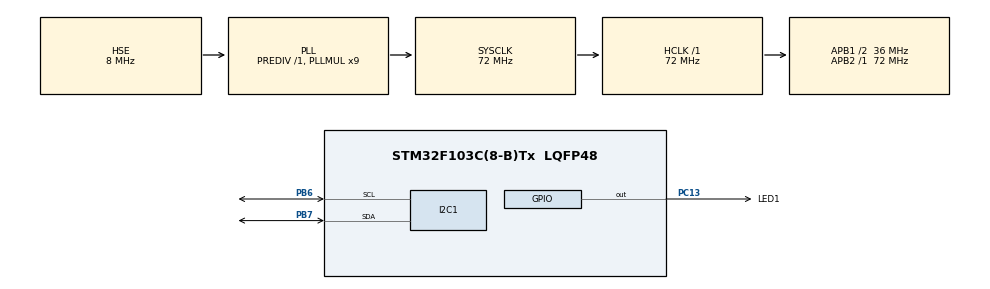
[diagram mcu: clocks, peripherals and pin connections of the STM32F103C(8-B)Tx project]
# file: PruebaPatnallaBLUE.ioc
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Dma.I2C1_RX.0.Direction=DMA_PERIPH_TO_MEMORY
Dma.I2C1_RX.0.Instance=DMA1_Channel7
Dma.I2C1_RX.0.MemDataAlignment=DMA_MDATAALIGN_BYTE
Dma.I2C1_RX.0.MemInc=DMA_MINC_ENABLE
Dma.I2C1_RX.0.Mode=DMA_NORMAL
Dma.I2C1_RX.0.PeriphDataAlignment=DMA_PDATAALIGN_BYTE
Dma.I2C1_RX.0.PeriphInc=DMA_PINC_DISABLE
Dma.I2C1_RX.0.Priority=DMA_PRIORITY_LOW
Dma.I2C1_TX.1.Direction=DMA_MEMORY_TO_PERIPH
Dma.I2C1_TX.1.Instance=DMA1_Channel6
Dma.I2C1_TX.1.MemDataAlignment=DMA_MDATAALIGN_BYTE
Dma.I2C1_TX.1.MemInc=DMA_MINC_ENABLE
Dma.I2C1_TX.1.Mode=DMA_NORMAL
Dma.I2C1_TX.1.PeriphDataAlignment=DMA_PDATAALIGN_BYTE
Dma.I2C1_TX.1.PeriphInc=DMA_PINC_DISABLE
Dma.I2C1_TX.1.Priority=DMA_PRIORITY_LOW
Dma.Request0=I2C1_RX
Dma.Request1=I2C1_TX
I2C1.I2C_Mode=I2C_Fast
Mcu.Family=STM32F1
Mcu.Name=STM32F103C(8-B)Tx
Mcu.Package=LQFP48
NVIC.DMA1_Channel6_IRQn=true\:0\:0\:false\:false\:true\:false\:true\:true
NVIC.DMA1_Channel7_IRQn=true\:0\:0\:false\:false\:true\:false\:true\:true
NVIC.I2C1_ER_IRQn=true\:0\:0\:false\:false\:true\:true\:true\:true
NVIC.I2C1_EV_IRQn=true\:0\:0\:false\:false\:true\:true\:true\:true
NVIC.PriorityGroup=NVIC_PRIORITYGROUP_4
NVIC.TIM4_IRQn=true\:0\:0\:false\:false\:true\:true\:true\:true
PA13.Mode=Serial_Wire
PA13.Signal=SYS_JTMS-SWDIO
PA14.Mode=Serial_Wire
PA14.Signal=SYS_JTCK-SWCLK
PB6.Mode=I2C
PB6.Signal=I2C1_SCL
PB7.Mode=I2C
PB7.Signal=I2C1_SDA
PC13-TAMPER-RTC.GPIO_Label=LED1
PC13-TAMPER-RTC.Signal=GPIO_Output
PC14-OSC32_IN.Mode=LSE-External-Oscillator
PC14-OSC32_IN.Signal=RCC_OSC32_IN
PC15-OSC32_OUT.Mode=LSE-External-Oscillator
PC15-OSC32_OUT.Signal=RCC_OSC32_OUT
PD0-OSC_IN.Mode=HSE-External-Oscillator
PD0-OSC_IN.Signal=RCC_OSC_IN
PD1-OSC_OUT.Mode=HSE-External-Oscillator
PD1-OSC_OUT.Signal=RCC_OSC_OUT
ProjectManager.HeapSize=0x200
ProjectManager.StackSize=0x400
ProjectManager.TargetToolchain=STM32CubeIDE
RCC.AHBFreq_Value=72000000
RCC.APB1CLKDivider=RCC_HCLK_DIV2
RCC.APB1Freq_Value=36000000
RCC.APB1TimFreq_Value=72000000
RCC.APB2Freq_Value=72000000
RCC.APB2TimFreq_Value=72000000
RCC.HCLKFreq_Value=72000000
RCC.PLLMUL=RCC_PLL_MUL9
RCC.PLLSourceVirtual=RCC_PLLSOURCE_HSE
RCC.SYSCLKFreq_VALUE=72000000
RCC.SYSCLKSource=RCC_SYSCLKSOURCE_PLLCLK
RCC.USBFreq_Value=72000000
TIM4.Period=7200
TIM4.Prescaler=1000
VP_TIM4_VS_ClockSourceINT.Mode=Internal
board=custom

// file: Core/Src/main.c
/* USER CODE BEGIN Header */
/**
  ******************************************************************************
  * @file           : main.c
  * @brief          : Main program body
  ******************************************************************************
  * @attention
  *
  * Copyright (c) 2025 STMicroelectronics.
  * All rights reserved.
  *
  * This software is licensed under terms that can be found in the LICENSE file
  * in the root directory of this software component.
  * If no LICENSE file comes with this software, it is provided AS-IS.
  *
  ******************************************************************************
  */
/* USER CODE END Header */
#include "main.h"

/* USER CODE BEGIN Includes */
#include "utilities.h"
#include "display.h"

/* USER CODE END Includes */

/* USER CODE BEGIN PD */
#define IS10MS					generalFlags.bit.b0
#define REFRESH_OLED			generalFlags.bit.b1
/* USER CODE END PD */

I2C_HandleTypeDef hi2c1;
DMA_HandleTypeDef hdma_i2c1_rx;
DMA_HandleTypeDef hdma_i2c1_tx;

TIM_HandleTypeDef htim4;

/* USER CODE BEGIN PV */
const unsigned char uner_logo[] = {
		0xff, 0xff, 0xff, 0xff, 0xff, 0xff, 0xff, 0xff, 0xff, 0xff, 0xff, 0xff, 0xff, 0xff, 0xff, 0xff,
		0xff, 0xff, 0xff, 0xff, 0xff, 0xff, 0xff, 0xff, 0xff, 0xff, 0xff, 0xff, 0xff, 0xff, 0xff, 0xff,
		0xff, 0xff, 0xff, 0xff, 0xff, 0xff, 0xff, 0xff, 0xff, 0xff, 0xff, 0xff, 0xff, 0xff, 0xff, 0xff,
		0xff, 0xff, 0xff, 0xff, 0xff, 0xff, 0xff, 0xff, 0xff, 0xff, 0xff, 0xff, 0xff, 0xff, 0xff, 0xff,
		0xff, 0xff, 0xff, 0xff, 0xff, 0xff, 0xff, 0xff, 0xff, 0xff, 0xff, 0xff, 0xff, 0xff, 0xff, 0xff,
		0xff, 0xff, 0xff, 0xff, 0xff, 0xff, 0xff, 0xff, 0xff, 0xff, 0xff, 0xff, 0xff, 0xff, 0xff, 0xff,
		0xff, 0xff, 0xff, 0xff, 0xff, 0xff, 0xff, 0xff, 0xff, 0xff, 0xff, 0xff, 0xff, 0xff, 0xff, 0xff,
		0xff, 0xff, 0xff, 0xff, 0xff, 0xff, 0xff, 0xff, 0xff, 0xff, 0xff, 0xff, 0xff, 0xff, 0xff, 0xff,
		0xff, 0xff, 0xff, 0xff, 0xff, 0xff, 0xff, 0xff, 0xff, 0xff, 0xff, 0xff, 0xff, 0xff, 0xff, 0xff,
		0xff, 0xff, 0xff, 0xff, 0xff, 0xff, 0xff, 0xff, 0xff, 0xff, 0xff, 0xff, 0xff, 0xff, 0xff, 0xff,
		0xff, 0xff, 0xff, 0xff, 0xff, 0xff, 0xff, 0xff, 0xff, 0xff, 0xff, 0xff, 0xff, 0xff, 0xff, 0xff,
		0xff, 0xff, 0xff, 0xff, 0xff, 0xff, 0xff, 0xff, 0xff, 0xff, 0xff, 0xff, 0xff, 0xff, 0xff, 0xff,
		0xff, 0xff, 0xff, 0xff, 0xff, 0xff, 0xff, 0x07, 0xff, 0xf8, 0x3f, 0xff, 0xff, 0xff, 0xff, 0xff,
		0xff, 0xff, 0xff, 0xff, 0xff, 0xff, 0xfc, 0x01, 0xff, 0xe0, 0x0f, 0xff, 0xff, 0xff, 0xff, 0xff,
		0xff, 0xff, 0xff, 0xff, 0xff, 0xff, 0xf8, 0x00, 0xff, 0x80, 0x0f, 0xff, 0xff, 0xff, 0xff, 0xff,
		0xff, 0xff, 0xff, 0xff, 0xff, 0xe7, 0xc0, 0x00, 0x3e, 0x00, 0x0f, 0xff, 0xff, 0xff, 0xff, 0xff,
		0xff, 0xff, 0xff, 0xff, 0xff, 0xe0, 0x00, 0x00, 0x00, 0x00, 0x0f, 0xff, 0xff, 0xff, 0xff, 0xff,
		0xff, 0xff, 0xff, 0xff, 0xff, 0xe0, 0x01, 0xfc, 0x00, 0x0f, 0xef, 0xff, 0xff, 0xff, 0xff, 0xff,
		0xff, 0xff, 0xff, 0xff, 0xff, 0xe0, 0x03, 0xfe, 0x00, 0x3f, 0xff, 0xff, 0xff, 0xff, 0xff, 0xff,
		0xff, 0xff, 0xff, 0xff, 0xff, 0xf0, 0x0f, 0xff, 0x80, 0x7f, 0xff, 0xff, 0xff, 0xff, 0xff, 0xff,
		0xff, 0xff, 0xff, 0xff, 0xff, 0xfc, 0x3f, 0xff, 0xe3, 0xff, 0xff, 0xff, 0xff, 0xff, 0xff, 0xff,
		0xff, 0xff, 0xff, 0xff, 0xff, 0xff, 0xff, 0xff, 0xff, 0xff, 0xff, 0xff, 0xff, 0xff, 0xff, 0xff,
		0xff, 0xff, 0xff, 0xff, 0xff, 0xff, 0xff, 0x07, 0xff, 0xf8, 0x3f, 0xff, 0xff, 0xff, 0xff, 0xff,
		0xff, 0xff, 0xff, 0xff, 0xff, 0xff, 0xfc, 0x01, 0xff, 0xe0, 0x0f, 0xff, 0xff, 0xff, 0xff, 0xff,
		0xff, 0xff, 0xff, 0xff, 0xff, 0xff, 0xf8, 0xf8, 0xff, 0xc7, 0xcf, 0xff, 0xff, 0xff, 0xff, 0xff,
		0xff, 0xff, 0xff, 0xff, 0xff, 0xe7, 0xe3, 0xfe, 0x3f, 0x1f, 0xff, 0xff, 0xff, 0xff, 0xff, 0xff,
		0xff, 0xff, 0xff, 0xff, 0xff, 0xe0, 0x07, 0xff, 0x00, 0x7f, 0xff, 0xff, 0xff, 0xff, 0xff, 0xff,
		0xff, 0xff, 0xff, 0xff, 0xff, 0xf8, 0x1f, 0xff, 0xc1, 0xff, 0xff, 0xff, 0xff, 0xff, 0xff, 0xff,
		0xff, 0xff, 0xff, 0xff, 0xff, 0xff, 0xff, 0xff, 0xff, 0xff, 0xff, 0xff, 0xff, 0xff, 0xff, 0xff,
		0xff, 0xff, 0xff, 0xff, 0xff, 0xff, 0xff, 0xff, 0xff, 0xff, 0xff, 0xff, 0xff, 0xff, 0xff, 0xff,
		0xff, 0xff, 0xff, 0xff, 0xff, 0xff, 0xff, 0xff, 0xff, 0xff, 0xff, 0xff, 0xff, 0xff, 0xff, 0xff,
		0xff, 0xff, 0xff, 0xff, 0xff, 0xff, 0xff, 0xff, 0xff, 0xff, 0xff, 0xff, 0xff, 0xff, 0xff, 0xff,
		0xff, 0xff, 0xff, 0xff, 0xff, 0xff, 0xff, 0xff, 0xff, 0xff, 0xff, 0xff, 0xff, 0xff, 0xff, 0xff,
		0xff, 0xff, 0xff, 0xff, 0xff, 0xff, 0xff, 0xff, 0xff, 0xff, 0xff, 0xff, 0xff, 0xff, 0xff, 0xff,
		0xff, 0xff, 0xff, 0xff, 0xff, 0xff, 0xff, 0xff, 0xff, 0xff, 0xff, 0xff, 0xff, 0xff, 0xff, 0xff,
		0xff, 0xff, 0xff, 0xff, 0xff, 0xe7, 0xdc, 0x79, 0xc0, 0x30, 0x3f, 0xff, 0xff, 0xff, 0xff, 0xff,
		0xff, 0xff, 0xff, 0xff, 0xff, 0xe7, 0xdc, 0x79, 0xc0, 0x30, 0x1f, 0xff, 0xff, 0xff, 0xff, 0xff,
		0xff, 0xff, 0xff, 0xff, 0xff, 0xe7, 0xdc, 0x79, 0xc7, 0xf3, 0x8f, 0xff, 0xff, 0xff, 0xff, 0xff,
		0xff, 0xff, 0xff, 0xff, 0xff, 0xe7, 0xdc, 0x39, 0xc7, 0xf3, 0x8f, 0xff, 0xff, 0xff, 0xff, 0xff,
		0xff, 0xff, 0xff, 0xff, 0xff, 0xe7, 0xdc, 0x39, 0xc7, 0xf3, 0x8f, 0xff, 0xff, 0xff, 0xff, 0xff,
		0xff, 0xff, 0xff, 0xff, 0xff, 0xe7, 0xdc, 0x99, 0xc7, 0xf3, 0x8f, 0xff, 0xff, 0xff, 0xff, 0xff,
		0xff, 0xff, 0xff, 0xff, 0xff, 0xe7, 0xdc, 0x99, 0xc0, 0x73, 0x8f, 0xff, 0xff, 0xff, 0xff, 0xff,
		0xff, 0xff, 0xff, 0xff, 0xff, 0xe7, 0xdc, 0xc9, 0xc0, 0x70, 0x1f, 0xff, 0xff, 0xff, 0xff, 0xff,
		0xff, 0xff, 0xff, 0xff, 0xff, 0xe7, 0xdc, 0xc9, 0xc0, 0x70, 0x3f, 0xff, 0xff, 0xff, 0xff, 0xff,
		0xff, 0xff, 0xff, 0xff, 0xff, 0xe7, 0xdc, 0xe1, 0xc7, 0xf3, 0x1f, 0xff, 0xff, 0xff, 0xff, 0xff,
		0xff, 0xff, 0xff, 0xff, 0xff, 0xe7, 0xdc, 0xe1, 0xc7, 0xf3, 0x1f, 0xff, 0xff, 0xff, 0xff, 0xff,
		0xff, 0xff, 0xff, 0xff, 0xff, 0xe7, 0xdc, 0xf1, 0xc7, 0xf3, 0x1f, 0xff, 0xff, 0xff, 0xff, 0xff,
		0xff, 0xff, 0xff, 0xff, 0xff, 0xe7, 0xdc, 0xf1, 0xc7, 0xf3, 0x9f, 0xff, 0xff, 0xff, 0xff, 0xff,
		0xff, 0xff, 0xff, 0xff, 0xff, 0xf3, 0x9c, 0xf9, 0xc0, 0x33, 0x8f, 0xff, 0xff, 0xff, 0xff, 0xff,
		0xff, 0xff, 0xff, 0xff, 0xff, 0xf0, 0x1c, 0xf9, 0xc0, 0x33, 0x8f, 0xff, 0xff, 0xff, 0xff, 0xff,
		0xff, 0xff, 0xff, 0xff, 0xff, 0xf8, 0x3e, 0xf9, 0xc0, 0x33, 0xcf, 0xff, 0xff, 0xff, 0xff, 0xff,
		0xff, 0xff, 0xff, 0xff, 0xff, 0xff, 0xff, 0xff, 0xff, 0xff, 0xff, 0xff, 0xff, 0xff, 0xff, 0xff,
		0xff, 0xff, 0xff, 0xff, 0xff, 0xff, 0xff, 0xff, 0xff, 0xff, 0xff, 0xff, 0xff, 0xff, 0xff, 0xff,
		0xff, 0xff, 0xff, 0xff, 0xff, 0xff, 0xff, 0xff, 0xff, 0xff, 0xff, 0xff, 0xff, 0xff, 0xff, 0xff,
		0xff, 0xff, 0xff, 0xff, 0xff, 0xff, 0xff, 0xff, 0xff, 0xff, 0xff, 0xff, 0xff, 0xff, 0xff, 0xff,
		0xff, 0xff, 0xff, 0xff, 0xff, 0xff, 0xff, 0xff, 0xff, 0xff, 0xff, 0xff, 0xff, 0xff, 0xff, 0xff,
		0xff, 0xff, 0xff, 0xff, 0xff, 0xff, 0xff, 0xff, 0xff, 0xff, 0xff, 0xff, 0xff, 0xff, 0xff, 0xff,
		0xff, 0xff, 0xff, 0xff, 0xff, 0xff, 0xff, 0xff, 0xff, 0xff, 0xff, 0xff, 0xff, 0xff, 0xff, 0xff,
		0xff, 0xff, 0xff, 0xff, 0xff, 0xff, 0xff, 0xff, 0xff, 0xff, 0xff, 0xff, 0xff, 0xff, 0xff, 0xff,
		0xff, 0xff, 0xff, 0xff, 0xff, 0xff, 0xff, 0xff, 0xff, 0xff, 0xff, 0xff, 0xff, 0xff, 0xff, 0xff,
		0xff, 0xff, 0xff, 0xff, 0xff, 0xff, 0xff, 0xff, 0xff, 0xff, 0xff, 0xff, 0xff, 0xff, 0xff, 0xff,
		0xff, 0xff, 0xff, 0xff, 0xff, 0xff, 0xff, 0xff, 0xff, 0xff, 0xff, 0xff, 0xff, 0xff, 0xff, 0xff,
		0xff, 0xff, 0xff, 0xff, 0xff, 0xff, 0xff, 0xff, 0xff, 0xff, 0xff, 0xff, 0xff, 0xff, 0xff, 0xff,
		0xff, 0xff, 0xff, 0xff, 0xff, 0xff, 0xff, 0xff, 0xff, 0xff, 0xff, 0xff, 0xff, 0xff, 0xff, 0xff
};

struct{
	uint8_t buffer[SSD1306_WIDTH * SSD1306_HEIGHT / 8];
}Display;

uint8_t is100ms = 10, is1s = 10;

u_flag generalFlags;
/* USER CODE END PV */

void SystemClock_Config(void);
static void MX_GPIO_Init(void);
static void MX_DMA_Init(void);
static void MX_I2C1_Init(void);
static void MX_TIM4_Init(void);
/* USER CODE BEGIN PFP */
void TASK_10ms();

e_system I2C_1_Abstract_Master_Transmit(uint16_t Dev_Address, uint8_t *p_Data, uint16_t _Size);

e_system I2C_1_Abstract_Master_Transmit_Blocking(uint16_t Dev_Address, uint8_t *p_Data, uint16_t _Size, uint32_t _Timeout);

e_system I2C_1_Abstract_Mem_Read_Blocking(uint16_t Dev_Address, uint8_t Mem_Adress, uint8_t Mem_AddSize, uint8_t *p_Data, uint16_t _Size, uint32_t _Timeout);

e_system I2C_1_Abstract_Mem_Write_Blocking(uint16_t Dev_Address, uint8_t Mem_Adress, uint8_t Mem_AddSize, uint8_t *p_Data, uint16_t _Size, uint32_t _Timeout);
/* USER CODE END PFP */

/* USER CODE BEGIN 0 */
void HAL_I2C_MemTxCpltCallback(I2C_HandleTypeDef *hi2c){
	if(hi2c->Devaddress == SSD1306_I2C_ADDR){
		Display_I2C_DMA_Ready(1);
	}
}

void HAL_TIM_PeriodElapsedCallback(TIM_HandleTypeDef *htim){ //			1/4000s
	if(htim->Instance == TIM4){
		IS10MS = TRUE;
	}
}
void TASK_10ms(){
	is100ms--;
	if(!is100ms){
		HAL_GPIO_TogglePin(LED1_GPIO_Port, LED1_Pin);
		is100ms = 10;

		Display_I2C_Refresh_Ready(1);
		/*if(HAL_I2C_Mem_Read_DMA(&hi2c1, MPU6050_ADDR, ACCEL_XOUT_REG, 1, MPU6050.data, 14) != HAL_OK){
			comm_sendCMD(&USB.data, USERTEXT, (uint8_t*)"putopepe", 8);
		}*/
	}
	IS10MS = 0;
}
/* USER CODE END 0 */

int main(void)
{

  /* MCU Configuration--------------------------------------------------------*/

  /* Reset of all peripherals, Initializes the Flash interface and the Systick. */
  HAL_Init();

  /* Configure the system clock */
  SystemClock_Config();

  /* Initialize all configured peripherals */
  MX_GPIO_Init();
  MX_DMA_Init();
  MX_I2C1_Init();
  MX_TIM4_Init();
  /* USER CODE BEGIN 2 */
  HAL_TIM_Base_Start_IT(&htim4);
  HAL_Delay(100);
  Display_Set_I2C_Master_Transmit(&I2C_1_Abstract_Master_Transmit, &I2C_1_Abstract_Master_Transmit_Blocking);
  if(Display_Init() == SYS_OK){
	  HAL_Delay(100);
  //Display_Fill(SSD1306_COLOR_WHITE);

	  Display_DrawBitmap(0,0, uner_logo, 128, 64, 1);
  }

  /* USER CODE END 2 */

  /* Infinite loop */
  while (1)
  {

    /* USER CODE BEGIN 3 */
	  Display_UpdateScreen();
	  if(IS10MS){
			TASK_10ms();
		}
  }
  /* USER CODE END 3 */
}

void SystemClock_Config(void)
{
  RCC_OscInitTypeDef RCC_OscInitStruct = {0};
  RCC_ClkInitTypeDef RCC_ClkInitStruct = {0};

  /** Initializes the RCC Oscillators according to the specified parameters
  * in the RCC_OscInitTypeDef structure.
  */
  RCC_OscInitStruct.OscillatorType = RCC_OSCILLATORTYPE_HSE;
  RCC_OscInitStruct.HSEState = RCC_HSE_ON;
  RCC_OscInitStruct.HSEPredivValue = RCC_HSE_PREDIV_DIV1;
  RCC_OscInitStruct.HSIState = RCC_HSI_ON;
  RCC_OscInitStruct.PLL.PLLState = RCC_PLL_ON;
  RCC_OscInitStruct.PLL.PLLSource = RCC_PLLSOURCE_HSE;
  RCC_OscInitStruct.PLL.PLLMUL = RCC_PLL_MUL9;
  if (HAL_RCC_OscConfig(&RCC_OscInitStruct) != HAL_OK)
  {
    Error_Handler();
  }

  /** Initializes the CPU, AHB and APB buses clocks
  */
  RCC_ClkInitStruct.ClockType = RCC_CLOCKTYPE_HCLK|RCC_CLOCKTYPE_SYSCLK
                              |RCC_CLOCKTYPE_PCLK1|RCC_CLOCKTYPE_PCLK2;
  RCC_ClkInitStruct.SYSCLKSource = RCC_SYSCLKSOURCE_PLLCLK;
  RCC_ClkInitStruct.AHBCLKDivider = RCC_SYSCLK_DIV1;
  RCC_ClkInitStruct.APB1CLKDivider = RCC_HCLK_DIV2;
  RCC_ClkInitStruct.APB2CLKDivider = RCC_HCLK_DIV1;

  if (HAL_RCC_ClockConfig(&RCC_ClkInitStruct, FLASH_LATENCY_2) != HAL_OK)
  {
    Error_Handler();
  }
}

static void MX_I2C1_Init(void)
{

  hi2c1.Instance = I2C1;
  hi2c1.Init.ClockSpeed = 400000;
  hi2c1.Init.DutyCycle = I2C_DUTYCYCLE_2;
  hi2c1.Init.OwnAddress1 = 0;
  hi2c1.Init.AddressingMode = I2C_ADDRESSINGMODE_7BIT;
  hi2c1.Init.DualAddressMode = I2C_DUALADDRESS_DISABLE;
  hi2c1.Init.OwnAddress2 = 0;
  hi2c1.Init.GeneralCallMode = I2C_GENERALCALL_DISABLE;
  hi2c1.Init.NoStretchMode = I2C_NOSTRETCH_DISABLE;
  if (HAL_I2C_Init(&hi2c1) != HAL_OK)
  {
    Error_Handler();
  }

}

static void MX_TIM4_Init(void)
{

  TIM_ClockConfigTypeDef sClockSourceConfig = {0};
  TIM_MasterConfigTypeDef sMasterConfig = {0};

  htim4.Instance = TIM4;
  htim4.Init.Prescaler = 1000;
  htim4.Init.CounterMode = TIM_COUNTERMODE_UP;
  htim4.Init.Period = 7200;
  htim4.Init.ClockDivision = TIM_CLOCKDIVISION_DIV1;
  htim4.Init.AutoReloadPreload = TIM_AUTORELOAD_PRELOAD_DISABLE;
  if (HAL_TIM_Base_Init(&htim4) != HAL_OK)
  {
    Error_Handler();
  }
  sClockSourceConfig.ClockSource = TIM_CLOCKSOURCE_INTERNAL;
  if (HAL_TIM_ConfigClockSource(&htim4, &sClockSourceConfig) != HAL_OK)
  {
    Error_Handler();
  }
  sMasterConfig.MasterOutputTrigger = TIM_TRGO_RESET;
  sMasterConfig.MasterSlaveMode = TIM_MASTERSLAVEMODE_DISABLE;
  if (HAL_TIMEx_MasterConfigSynchronization(&htim4, &sMasterConfig) != HAL_OK)
  {
    Error_Handler();
  }

}

static void MX_DMA_Init(void)
{

  /* DMA controller clock enable */
  __HAL_RCC_DMA1_CLK_ENABLE();

  /* DMA interrupt init */
  /* DMA1_Channel6_IRQn interrupt configuration */
  HAL_NVIC_SetPriority(DMA1_Channel6_IRQn, 0, 0);
  HAL_NVIC_EnableIRQ(DMA1_Channel6_IRQn);
  /* DMA1_Channel7_IRQn interrupt configuration */
  HAL_NVIC_SetPriority(DMA1_Channel7_IRQn, 0, 0);
  HAL_NVIC_EnableIRQ(DMA1_Channel7_IRQn);

}

static void MX_GPIO_Init(void)
{
  GPIO_InitTypeDef GPIO_InitStruct = {0};

  /* GPIO Ports Clock Enable */
  __HAL_RCC_GPIOC_CLK_ENABLE();
  __HAL_RCC_GPIOD_CLK_ENABLE();
  __HAL_RCC_GPIOA_CLK_ENABLE();
  __HAL_RCC_GPIOB_CLK_ENABLE();

  /*Configure GPIO pin Output Level */
  HAL_GPIO_WritePin(LED1_GPIO_Port, LED1_Pin, GPIO_PIN_RESET);

  /*Configure GPIO pin : LED1_Pin */
  GPIO_InitStruct.Pin = LED1_Pin;
  GPIO_InitStruct.Mode = GPIO_MODE_OUTPUT_PP;
  GPIO_InitStruct.Pull = GPIO_NOPULL;
  GPIO_InitStruct.Speed = GPIO_SPEED_FREQ_LOW;
  HAL_GPIO_Init(LED1_GPIO_Port, &GPIO_InitStruct);

}

/* USER CODE BEGIN 4 */
e_system I2C_1_Abstract_Master_Transmit(uint16_t Dev_Address, uint8_t *p_Data, uint16_t _Size){
	return (e_system)HAL_I2C_Mem_Write_DMA(&hi2c1, Dev_Address, 0x40, 1, p_Data, _Size);
}

e_system I2C_1_Abstract_Master_Transmit_Blocking(uint16_t Dev_Address, uint8_t *p_Data, uint16_t _Size, uint32_t _Timeout){
	return (e_system)HAL_I2C_Master_Transmit(&hi2c1, Dev_Address, p_Data, _Size, _Timeout);
}

e_system I2C_1_Abstract_Mem_Write_Blocking(uint16_t Dev_Address, uint8_t Mem_Adress, uint8_t Mem_AddSize, uint8_t *p_Data, uint16_t _Size, uint32_t _Timeout){
	return HAL_I2C_Mem_Write(&hi2c1, Dev_Address, Mem_Adress, Mem_AddSize, p_Data, _Size, _Timeout);
}

e_system I2C_1_Abstract_Mem_Read_Blocking(uint16_t Dev_Address, uint8_t Mem_Adress, uint8_t Mem_AddSize, uint8_t *p_Data, uint16_t _Size, uint32_t _Timeout){
	return HAL_I2C_Mem_Read(&hi2c1, Dev_Address, Mem_Adress, Mem_AddSize, p_Data, _Size, _Timeout);
}
/* USER CODE END 4 */

void Error_Handler(void)
{
  __disable_irq();
  while (1)
  {
  }
}
